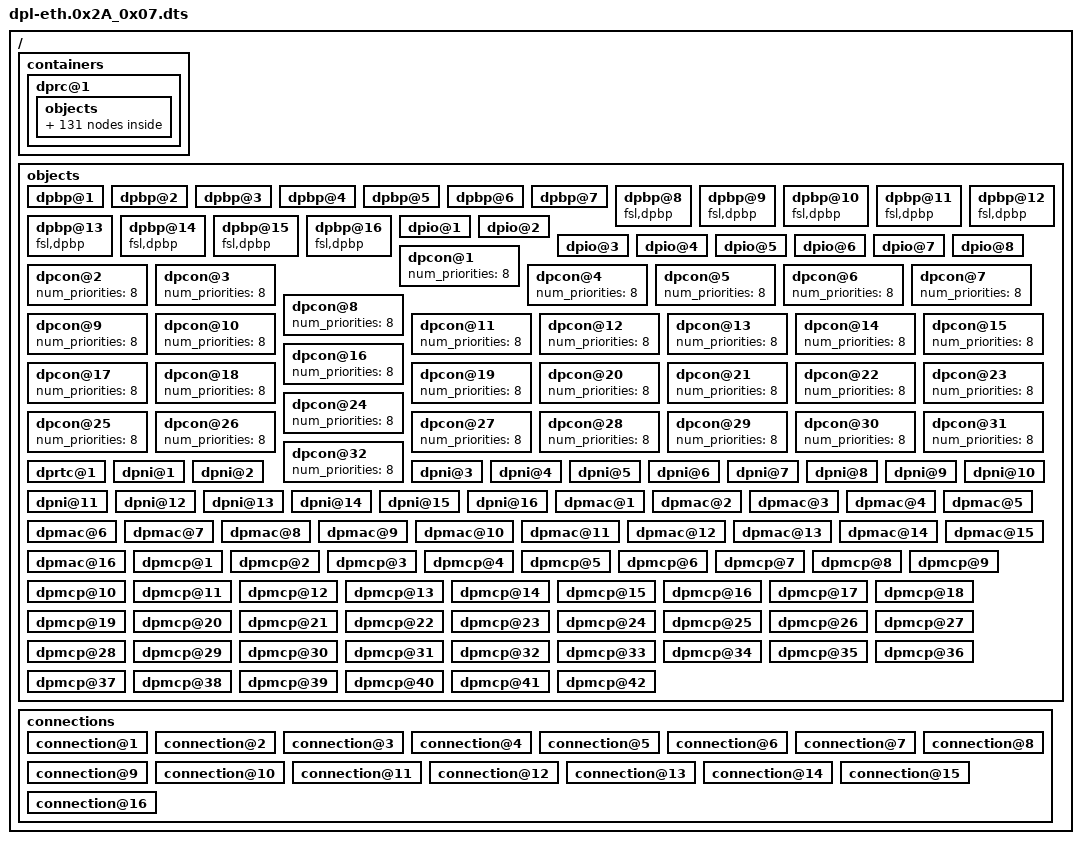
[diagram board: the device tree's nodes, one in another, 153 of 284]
/*
 * Copyright 2015-2016 Freescale Semiconductor, Inc.
 * Copyright 2017 NXP
 *
 * Redistribution and use in source and binary forms, with or without
 * modification, are permitted provided that the following conditions are met:
 *   * Redistributions of source code must retain the above copyright
 *     notice, this list of conditions and the following disclaimer.
 *   * Redistributions in binary form must reproduce the above copyright
 *     notice, this list of conditions and the following disclaimer in the
 *     documentation and/or other materials provided with the distribution.
 *   * Neither the name of the above-listed copyright holders nor the
 *     names of any contributors may be used to endorse or promote products
 *     derived from this software without specific prior written permission.
 *
 * THIS SOFTWARE IS PROVIDED BY THE COPYRIGHT HOLDERS AND CONTRIBUTORS "AS IS"
 * AND ANY EXPRESS OR IMPLIED WARRANTIES, INCLUDING, BUT NOT LIMITED TO, THE
 * IMPLIED WARRANTIES OF MERCHANTABILITY AND FITNESS FOR A PARTICULAR PURPOSE
 * ARE DISCLAIMED. IN NO EVENT SHALL THE COPYRIGHT HOLDERS OR CONTRIBUTORS BE
 * LIABLE FOR ANY DIRECT, INDIRECT, INCIDENTAL, SPECIAL, EXEMPLARY, OR
 * CONSEQUENTIAL DAMAGES (INCLUDING, BUT NOT LIMITED TO, PROCUREMENT OF
 * SUBSTITUTE GOODS OR SERVICES; LOSS OF USE, DATA, OR PROFITS; OR BUSINESS
 * INTERRUPTION) HOWEVER CAUSED AND ON ANY THEORY OF LIABILITY, WHETHER IN
 * CONTRACT, STRICT LIABILITY, OR TORT (INCLUDING NEGLIGENCE OR OTHERWISE)
 * ARISING IN ANY WAY OUT OF THE USE OF THIS SOFTWARE, EVEN IF ADVISED OF THE
 * POSSIBILITY OF SUCH DAMAGE.
 */

/*
 * This DPL showcases one Linux configuration for SerDes 0x2a_0x07
 */

/dts-v1/;
/ {
	/*****************************************************************
         * Containers
         *****************************************************************/
	containers {
		dprc@1 {
			parent = "none";
			options = "DPRC_CFG_OPT_SPAWN_ALLOWED" , "DPRC_CFG_OPT_ALLOC_ALLOWED", "DPRC_CFG_OPT_IRQ_CFG_ALLOWED";

			objects {
				/* ------------- DPMACs --------------*/
				/* For SerDes 0x2a_07, 8 DPMACs are mapped
				 * on the 8 XFI ports and 8 DPMACs
				 * are mapped on the 8 SGMII ports of the PCIe
				 * Slot 4 riser card.
				 */
				obj@101 {
					obj_name = "dpmac@1";
				};
				obj@102 {
					obj_name = "dpmac@2";
				};
				obj@103 {
					obj_name = "dpmac@3";
				};
				obj@104 {
					obj_name = "dpmac@4";
				};
				obj@105 {
					obj_name = "dpmac@5";
				};
				obj@106 {
					obj_name = "dpmac@6";
				};
				obj@107 {
					obj_name = "dpmac@7";
				};
				obj@108 {
					obj_name = "dpmac@8";
				};
				obj@109 {
					obj_name = "dpmac@9";
				};
				obj@110 {
					obj_name = "dpmac@10";
				};
				obj@111 {
					obj_name = "dpmac@11";
				};
				obj@112 {
					obj_name = "dpmac@12";
				};
				obj@113 {
					obj_name = "dpmac@13";
				};
				obj@114 {
					obj_name = "dpmac@14";
				};
				obj@115 {
					obj_name = "dpmac@15";
				};
				obj@116 {
					obj_name = "dpmac@16";
				};

				/* ------------ DPNIs --------------*/
				obj@201 {
					obj_name = "dpni@1";
				};
				obj@202 {
					obj_name = "dpni@2";
				};
				obj@203 {
					obj_name = "dpni@3";
				};
				obj@204 {
					obj_name = "dpni@4";
				};
				obj@205 {
					obj_name = "dpni@5";
				};
				obj@206 {
					obj_name = "dpni@6";
				};
				obj@207 {
					obj_name = "dpni@7";
				};
				obj@208 {
					obj_name = "dpni@8";
				};
				obj@209 {
					obj_name = "dpni@9";
				};
				obj@210 {
					obj_name = "dpni@10";
				};
				obj@211 {
					obj_name = "dpni@11";
				};
				obj@212 {
					obj_name = "dpni@12";
				};
				obj@213 {
					obj_name = "dpni@13";
				};
				obj@214 {
					obj_name = "dpni@14";
				};
				obj@215 {
					obj_name = "dpni@15";
				};
				obj@216 {
					obj_name = "dpni@16";
				};

				/* ------------ DPBPs --------------*/
				/* Each DPNI uses one DPBP */
				obj@301 {
					obj_name="dpbp@1";
				};
				obj@302 {
					obj_name="dpbp@2";
				};
				obj@303 {
					obj_name="dpbp@3";
				};
				obj@304 {
					obj_name="dpbp@4";
				};
				obj@305 {
					obj_name="dpbp@5";
				};
				obj@306 {
					obj_name="dpbp@6";
				};
				obj@307 {
					obj_name="dpbp@7";
				};
				obj@308 {
					obj_name = "dpbp@8";
				};
				obj@309 {
					obj_name = "dpbp@9";
				};
				obj@310 {
					obj_name = "dpbp@10";
				};
				obj@311 {
					obj_name = "dpbp@11";
				};
				obj@312 {
					obj_name = "dpbp@12";
				};
				obj@313 {
					obj_name = "dpbp@13";
				};
				obj@314 {
					obj_name = "dpbp@14";
				};
				obj@315 {
					obj_name = "dpbp@15";
				};
				obj@316 {
					obj_name = "dpbp@16";
				};


				/* ------------ DPMCPs --------------*/
				/* Ethernet DPMCPs:
				*  One for every DPNI, one for every DPMAC, then
				*  one more for DPIO.
				*
				*  Next: DPRC and restool, VFIO and possibly
				*  others from the kernel have DPMCP requirements.
				*  We'll just add a slack of 10 MCPs.
				*/
				obj@801 {
					obj_name="dpmcp@1";
				};
				obj@802 {
					obj_name="dpmcp@2";
				};
				obj@803 {
					obj_name="dpmcp@3";
				};
				obj@804 {
					obj_name="dpmcp@4";
				};
				obj@805 {
					obj_name="dpmcp@5";
				};
				obj@806 {
					obj_name="dpmcp@6";
				};
				obj@807 {
					obj_name="dpmcp@7";
				};
				obj@808 {
					obj_name="dpmcp@8";
				};
				obj@809 {
					obj_name="dpmcp@9";
				};
				obj@810 {
					obj_name="dpmcp@10";
				};
				obj@811 {
					obj_name="dpmcp@11";
				};
				obj@812 {
					obj_name="dpmcp@12";
				};
				obj@813 {
					obj_name="dpmcp@13";
				};
				obj@814 {
					obj_name="dpmcp@14";
				};
				obj@815 {
					obj_name="dpmcp@15";
				};
				obj@816 {
					obj_name="dpmcp@16";
				};
				obj@817 {
					obj_name="dpmcp@17";
				};
				obj@818 {
					obj_name="dpmcp@18";
				};
				obj@819 {
					obj_name="dpmcp@19";
				};
				obj@820 {
					obj_name="dpmcp@20";
				};
				obj@821 {
					obj_name="dpmcp@21";
				};
				obj@822 {
					obj_name="dpmcp@22";
				};
				obj@823 {
					obj_name="dpmcp@23";
				};
				obj@824 {
					obj_name="dpmcp@24";
				};
				obj@825 {
					obj_name="dpmcp@25";
				};
				obj@826 {
					obj_name="dpmcp@26";
				};
				obj@827 {
					obj_name="dpmcp@27";
				};
				obj@828 {
					obj_name="dpmcp@28";
				};
				obj@829 {
					obj_name="dpmcp@29";
				};
				obj@830 {
					obj_name="dpmcp@30";
				};
				obj@831 {
					obj_name="dpmcp@31";
				};
				obj@832 {
					obj_name="dpmcp@32";
				};
				obj@833 {
					obj_name="dpmcp@33";
				};
				obj@834 {
					obj_name="dpmcp@34";
				};
				obj@835 {
					obj_name="dpmcp@35";
				};
				obj@836 {
					obj_name="dpmcp@36";
				};
				obj@837 {
					obj_name="dpmcp@37";
				};
				obj@838 {
					obj_name="dpmcp@38";
				};
				obj@839 {
					obj_name="dpmcp@39";
				};
				obj@840 {
					obj_name="dpmcp@40";
				};
				obj@841 {
					obj_name="dpmcp@41";
				};
				obj@842 {
					obj_name="dpmcp@42";
				};
				/* ------------ DPIOs --------------*/
				/* One DPIO for each online CPU. This is a
				 * maximal configuration.
				 */
				obj@401 {
					obj_name = "dpio@1";
				};
				obj@402 {
					obj_name = "dpio@2";
				};
				obj@403 {
					obj_name = "dpio@3";
				};
				obj@404 {
					obj_name = "dpio@4";
				};
				obj@405 {
					obj_name = "dpio@5";
				};
				obj@406 {
					obj_name = "dpio@6";
				};
				obj@407 {
					obj_name = "dpio@7";
				};
				obj@408 {
					obj_name = "dpio@8";
				};

				/* ------------ DPCONs --------------*/
				/* Used by DPNIs in Linux for CDAN-based dequeueing.
				 * Ideally, there should be one DPCON per {DPNIxDPIO}
				 * combination. but at the moment we're constrained
				 * by the hard limit of 64 8-prio DPCONs. Moreover,
				 * each DPIO object consumes one DPCON, so there are
				 * only 56 left for all DPNIs
				 */
				obj@501 {
					obj_name="dpcon@1";
				};
				obj@502 {
					obj_name="dpcon@2";
				};
				obj@503 {
					obj_name="dpcon@3";
				};
				obj@504 {
					obj_name="dpcon@4";
				};
				obj@505 {
					obj_name="dpcon@5";
				};
				obj@506 {
					obj_name="dpcon@6";
				};
				obj@507 {
					obj_name="dpcon@7";
				};
				obj@508 {
					obj_name="dpcon@8";
				};
				obj@509 {
					obj_name="dpcon@9";
				};
				obj@510 {
					obj_name="dpcon@10";
				};
				obj@511 {
					obj_name="dpcon@11";
				};
				obj@512 {
					obj_name="dpcon@12";
				};
				obj@513 {
					obj_name="dpcon@13";
				};
				obj@514 {
					obj_name="dpcon@14";
				};
				obj@515 {
					obj_name="dpcon@15";
				};
				obj@516 {
					obj_name="dpcon@16";
				};
				obj@517 {
					obj_name="dpcon@17";
				};
				obj@518 {
					obj_name="dpcon@18";
				};
				obj@519 {
					obj_name="dpcon@19";
				};
				obj@520 {
					obj_name="dpcon@20";
				};
				obj@521 {
					obj_name="dpcon@21";
				};
				obj@522 {
					obj_name="dpcon@22";
				};
				obj@523 {
					obj_name="dpcon@23";
				};
				obj@524 {
					obj_name="dpcon@24";
				};
				obj@525 {
					obj_name="dpcon@25";
				};
				obj@526 {
					obj_name="dpcon@26";
				};
				obj@527 {
					obj_name="dpcon@27";
				};
				obj@528 {
					obj_name="dpcon@28";
				};
				obj@529 {
					obj_name="dpcon@29";
				};
				obj@530 {
					obj_name="dpcon@30";
				};
				obj@531 {
					obj_name="dpcon@31";
				};
				obj@532 {
					obj_name="dpcon@32";
				};

				/* ------------ DPRTC --------------*/
				obj@901 {
					obj_name="dprtc@1";
				};
			};
		};
	};

	/*****************************************************************
         * Objects
         *****************************************************************/
	objects {

		/* ------------ DPBP --------------*/
		dpbp@1 {
		};
		dpbp@2 {
		};
		dpbp@3 {
		};
		dpbp@4 {
		};
		dpbp@5 {
		};
		dpbp@6 {
		};
		dpbp@7 {
		};
		dpbp@8 {
			compatible= "fsl,dpbp";
		};
		dpbp@9 {
			compatible= "fsl,dpbp";
		};
		dpbp@10 {
			compatible= "fsl,dpbp";
		};
		dpbp@11 {
			compatible= "fsl,dpbp";
		};
		dpbp@12 {
			compatible= "fsl,dpbp";
		};
		dpbp@13 {
			compatible= "fsl,dpbp";
		};
		dpbp@14 {
			compatible= "fsl,dpbp";
		};
		dpbp@15 {
			compatible= "fsl,dpbp";
		};
		dpbp@16 {
			compatible= "fsl,dpbp";
		};
		/* ------------ DPIO --------------*/
		dpio@1 {
			channel_mode = "DPIO_LOCAL_CHANNEL";
			num_priorities = <8>;
		};
		dpio@2 {
			channel_mode = "DPIO_LOCAL_CHANNEL";
			num_priorities = <8>;
		};
		dpio@3 {
			channel_mode = "DPIO_LOCAL_CHANNEL";
			num_priorities = <8>;
		};
		dpio@4 {
			channel_mode = "DPIO_LOCAL_CHANNEL";
			num_priorities = <8>;
		};
		dpio@5 {
			channel_mode = "DPIO_LOCAL_CHANNEL";
			num_priorities = <8>;
		};
		dpio@6 {
			channel_mode = "DPIO_LOCAL_CHANNEL";
			num_priorities = <8>;
		};
		dpio@7 {
			channel_mode = "DPIO_LOCAL_CHANNEL";
			num_priorities = <8>;
		};
		dpio@8 {
			channel_mode = "DPIO_LOCAL_CHANNEL";
			num_priorities = <8>;
		};
		/* ------------ DPCON --------------*/
		/* Currently, only 8-WQ channels are supported. */
		dpcon@1 {
			num_priorities=<8>;
		};
		dpcon@2 {
			num_priorities=<8>;
		};
		dpcon@3 {
			num_priorities=<8>;
		};
		dpcon@4 {
			num_priorities=<8>;
		};
		dpcon@5 {
			num_priorities=<8>;
		};
		dpcon@6 {
			num_priorities=<8>;
		};
		dpcon@7 {
			num_priorities=<8>;
		};
		dpcon@8 {
			num_priorities=<8>;
		};
		dpcon@9 {
			num_priorities=<8>;
		};
		dpcon@10 {
			num_priorities=<8>;
		};
		dpcon@11 {
			num_priorities=<8>;
		};
		dpcon@12 {
			num_priorities=<8>;
		};
		dpcon@13 {
			num_priorities=<8>;
		};
		dpcon@14 {
			num_priorities=<8>;
		};
		dpcon@15 {
			num_priorities=<8>;
		};
		dpcon@16 {
			num_priorities=<8>;
		};
		dpcon@17 {
			num_priorities=<8>;
		};
		dpcon@18 {
			num_priorities=<8>;
		};
		dpcon@19 {
			num_priorities=<8>;
		};
		dpcon@20 {
			num_priorities=<8>;
		};
		dpcon@21 {
			num_priorities=<8>;
		};
		dpcon@22 {
			num_priorities=<8>;
		};
		dpcon@23 {
			num_priorities=<8>;
		};
		dpcon@24 {
			num_priorities=<8>;
		};
		dpcon@25 {
			num_priorities=<8>;
		};
		dpcon@26 {
			num_priorities=<8>;
		};
		dpcon@27 {
			num_priorities=<8>;
		};
		dpcon@28 {
			num_priorities=<8>;
		};
		dpcon@29 {
			num_priorities=<8>;
		};
		dpcon@30 {
			num_priorities=<8>;
		};
		dpcon@31 {
			num_priorities=<8>;
		};
		dpcon@32 {
			num_priorities=<8>;
		};

		/* ------------ DPRTC --------------*/
		dprtc@1 {
		};

		/* ------------ DPNI --------------*/
		/* Common DPNI properties:
		 *
		 * mac_addr = <0x00 0x00 0x00 0x00 0x00 0x00>;
		 *   An all-zero value will cause the Eth driver to auto-generate
		 *   a random (but valid) MAC address. Reduces DPL maintenance.
		 *
		 * max_senders = <8>;
		 *   Number of DPIOs to use for transmission.
		 *
		 * max_dist_per_tc = <7>;
		 *   Number of Rx cores to configure hash distribution towards.
		 *   Un-intuitively, '7' actually means '8' ("add 1 and round to
		 *   the nearest power of 2").
		 *
		 * max_dist_key_size = <24>;
		 *    Maximum hash key length in bytes.
		 *
		 * Other possible properties:
		 *  max_unicast_filters
		 *  max_multicast_filters
		 *  max_vlan_filters
		 *  max_qos_entries
		 *  max_qos_key_size
		 *
		 * Unless otherwise stated, attributes with value <0> receive a
		 * default value from the MC and can be skipped from the DPL
		 * altogether.
		 */
		dpni@1 {
			type = "DPNI_TYPE_NIC";
			mac_addr = <0x00 0x00 0x00 0x00 0x00 0x00>;
			max_senders = <8>;
			options = "DPNI_OPT_MULTICAST_FILTER", "DPNI_OPT_UNICAST_FILTER", "DPNI_OPT_DIST_HASH", "DPNI_OPT_DIST_FS";
			max_tcs = <1>;
			max_dist_per_tc = <1>;
			max_dist_key_size = <24>;
		};
		dpni@2 {
			type = "DPNI_TYPE_NIC";
			mac_addr = <0x00 0x00 0x00 0x00 0x00 0x00>;
			max_senders = <8>;
			options = "DPNI_OPT_MULTICAST_FILTER", "DPNI_OPT_UNICAST_FILTER", "DPNI_OPT_DIST_HASH", "DPNI_OPT_DIST_FS";
			max_tcs = <1>;
			max_dist_per_tc = <1>;
			max_dist_key_size = <24>;
		};
		dpni@3 {
			type = "DPNI_TYPE_NIC";
			mac_addr = <0x00 0x00 0x00 0x00 0x00 0x00>;
			max_senders = <8>;
			options = "DPNI_OPT_MULTICAST_FILTER", "DPNI_OPT_UNICAST_FILTER", "DPNI_OPT_DIST_HASH", "DPNI_OPT_DIST_FS";
			max_tcs = <1>;
			max_dist_per_tc = <1>;
			max_dist_key_size = <24>;
		};
		dpni@4 {
			type = "DPNI_TYPE_NIC";
			mac_addr = <0x00 0x00 0x00 0x00 0x00 0x00>;
			max_senders = <8>;
			options = "DPNI_OPT_MULTICAST_FILTER", "DPNI_OPT_UNICAST_FILTER", "DPNI_OPT_DIST_HASH", "DPNI_OPT_DIST_FS";
			max_tcs = <1>;
			max_dist_per_tc = <1>;
			max_dist_key_size = <24>;
		};
		dpni@5 {
			type = "DPNI_TYPE_NIC";
			mac_addr = <0x00 0x00 0x00 0x00 0x00 0x00>;
			max_senders = <8>;
			options = "DPNI_OPT_MULTICAST_FILTER", "DPNI_OPT_UNICAST_FILTER", "DPNI_OPT_DIST_HASH", "DPNI_OPT_DIST_FS";
			max_tcs = <1>;
			max_dist_per_tc = <1>;
			max_dist_key_size = <24>;
		};
		dpni@6 {
			type = "DPNI_TYPE_NIC";
			mac_addr = <0x00 0x00 0x00 0x00 0x00 0x00>;
			max_senders = <8>;
			options = "DPNI_OPT_MULTICAST_FILTER", "DPNI_OPT_UNICAST_FILTER", "DPNI_OPT_DIST_HASH", "DPNI_OPT_DIST_FS";
			max_tcs = <1>;
			max_dist_per_tc = <1>;
			max_dist_key_size = <24>;
		};
		dpni@7 {
			type = "DPNI_TYPE_NIC";
			mac_addr = <0x00 0x00 0x00 0x00 0x00 0x00>;
			max_senders = <8>;
			options = "DPNI_OPT_MULTICAST_FILTER", "DPNI_OPT_UNICAST_FILTER", "DPNI_OPT_DIST_HASH", "DPNI_OPT_DIST_FS";
			max_tcs = <1>;
			max_dist_per_tc = <1>;
			max_dist_key_size = <24>;
		};
		dpni@8 {
			type = "DPNI_TYPE_NIC";
			mac_addr = <0x00 0x00 0x00 0x00 0x00 0x00>;
			max_senders = <8>;
			options = "DPNI_OPT_MULTICAST_FILTER", "DPNI_OPT_UNICAST_FILTER", "DPNI_OPT_DIST_HASH", "DPNI_OPT_DIST_FS";
			max_tcs = <1>;
			max_dist_per_tc = <1>;
			max_dist_key_size = <24>;
		};
		dpni@9 {
			type = "DPNI_TYPE_NIC";
			mac_addr = <0x00 0x00 0x00 0x00 0x00 0x00>;
			max_senders = <8>;
			options = "DPNI_OPT_MULTICAST_FILTER", "DPNI_OPT_UNICAST_FILTER", "DPNI_OPT_DIST_HASH", "DPNI_OPT_DIST_FS";
			max_tcs = <1>;
			max_dist_per_tc = <1>;
			max_dist_key_size = <24>;
		};
		dpni@10 {
			type = "DPNI_TYPE_NIC";
			mac_addr = <0x00 0x00 0x00 0x00 0x00 0x00>;
			max_senders = <8>;
			options = "DPNI_OPT_MULTICAST_FILTER", "DPNI_OPT_UNICAST_FILTER", "DPNI_OPT_DIST_HASH", "DPNI_OPT_DIST_FS";
			max_tcs = <1>;
			max_dist_per_tc = <1>;
			max_dist_key_size = <24>;
		};
		dpni@11 {
			type = "DPNI_TYPE_NIC";
			mac_addr = <0x00 0x00 0x00 0x00 0x00 0x00>;
			max_senders = <8>;
			options = "DPNI_OPT_MULTICAST_FILTER", "DPNI_OPT_UNICAST_FILTER", "DPNI_OPT_DIST_HASH", "DPNI_OPT_DIST_FS";
			max_tcs = <1>;
			max_dist_per_tc = <1>;
			max_dist_key_size = <24>;
		};
		dpni@12 {
			type = "DPNI_TYPE_NIC";
			mac_addr = <0x00 0x00 0x00 0x00 0x00 0x00>;
			max_senders = <8>;
			options = "DPNI_OPT_MULTICAST_FILTER", "DPNI_OPT_UNICAST_FILTER", "DPNI_OPT_DIST_HASH", "DPNI_OPT_DIST_FS";
			max_tcs = <1>;
			max_dist_per_tc = <1>;
			max_dist_key_size = <24>;
		};
		dpni@13 {
			type = "DPNI_TYPE_NIC";
			mac_addr = <0x00 0x00 0x00 0x00 0x00 0x00>;
			max_senders = <8>;
			options = "DPNI_OPT_MULTICAST_FILTER", "DPNI_OPT_UNICAST_FILTER", "DPNI_OPT_DIST_HASH", "DPNI_OPT_DIST_FS";
			max_tcs = <1>;
			max_dist_per_tc = <1>;
			max_dist_key_size = <24>;
		};
		dpni@14 {
			type = "DPNI_TYPE_NIC";
			mac_addr = <0x00 0x00 0x00 0x00 0x00 0x00>;
			max_senders = <8>;
			options = "DPNI_OPT_MULTICAST_FILTER", "DPNI_OPT_UNICAST_FILTER", "DPNI_OPT_DIST_HASH", "DPNI_OPT_DIST_FS";
			max_tcs = <1>;
			max_dist_per_tc = <1>;
			max_dist_key_size = <24>;
		};
		dpni@15 {
			type = "DPNI_TYPE_NIC";
			mac_addr = <0x00 0x00 0x00 0x00 0x00 0x00>;
			max_senders = <8>;
			options = "DPNI_OPT_MULTICAST_FILTER", "DPNI_OPT_UNICAST_FILTER", "DPNI_OPT_DIST_HASH", "DPNI_OPT_DIST_FS";
			max_tcs = <1>;
			max_dist_per_tc = <1>;
			max_dist_key_size = <24>;
		};
		dpni@16 {
			type = "DPNI_TYPE_NIC";
			mac_addr = <0x00 0x00 0x00 0x00 0x00 0x00>;
			max_senders = <8>;
			options = "DPNI_OPT_MULTICAST_FILTER", "DPNI_OPT_UNICAST_FILTER", "DPNI_OPT_DIST_HASH", "DPNI_OPT_DIST_FS";
			max_tcs = <1>;
			max_dist_per_tc = <1>;
			max_dist_key_size = <24>;
		};

		/* ------------ DPMAC --------------*/
		dpmac@1 {
		};
		dpmac@2 {
		};
		dpmac@3 {
		};
		dpmac@4 {
		};
		dpmac@5 {
		};
		dpmac@6 {
		};
		dpmac@7 {
		};
		dpmac@8 {
		};
		dpmac@9 {
		};
		dpmac@10 {
		};
		dpmac@11 {
		};
		dpmac@12 {
		};
		dpmac@13 {
		};
		dpmac@14 {
		};
		dpmac@15 {
		};
		dpmac@16 {
		};

		/* ------------ DPMCP --------------*/
		dpmcp@1 {
		};
		dpmcp@2 {
		};
		dpmcp@3 {
		};
		dpmcp@4 {
		};
		dpmcp@5 {
		};
		dpmcp@6 {
		};
		dpmcp@7 {
		};
		dpmcp@8 {
		};
		dpmcp@9 {
		};
		dpmcp@10 {
		};
		dpmcp@11 {
		};
		dpmcp@12 {
		};
		dpmcp@13 {
		};
		dpmcp@14 {
		};
		dpmcp@15 {
		};
		dpmcp@16 {
		};
		dpmcp@17 {
		};
		dpmcp@18 {
		};
		dpmcp@19 {
		};
		dpmcp@20 {
		};
		dpmcp@21 {
		};
		dpmcp@22 {
		};
		dpmcp@23 {
		};
		dpmcp@24 {
		};
		dpmcp@25 {
		};
		dpmcp@26 {
		};
		dpmcp@27 {
		};
		dpmcp@28 {
		};
		dpmcp@29 {
		};
		dpmcp@30 {
		};
		dpmcp@31 {
		};
		dpmcp@32 {
		};
		dpmcp@33 {
		};
		dpmcp@34 {
		};
		dpmcp@35 {
		};
		dpmcp@36 {
		};
		dpmcp@37 {
		};
		dpmcp@38 {
		};
		dpmcp@39 {
		};
		dpmcp@40 {
		};
		dpmcp@41 {
		};
		dpmcp@42 {
		};
	};

	/*****************************************************************
         * Connections
         *****************************************************************/
	connections {
		/* XFIs */
		connection@1{
			endpoint1 = "dpni@1";
			endpoint2 = "dpmac@1";
		};
		connection@2{
			endpoint1 = "dpni@2";
			endpoint2 = "dpmac@2";
		};
		connection@3{
			endpoint1 = "dpni@3";
			endpoint2 = "dpmac@3";
		};
		connection@4{
			endpoint1 = "dpni@4";
			endpoint2 = "dpmac@4";
		};
		connection@5{
			endpoint1 = "dpni@5";
			endpoint2 = "dpmac@5";
		};
		connection@6{
			endpoint1 = "dpni@6";
			endpoint2 = "dpmac@6";
		};
		connection@7{
			endpoint1 = "dpni@7";
			endpoint2 = "dpmac@7";
		};
		connection@8{
			endpoint1 = "dpni@8";
			endpoint2 = "dpmac@8";
		};
	/* SGMIIs */
		connection@9{
			endpoint1 = "dpni@9";
			endpoint2 = "dpmac@9";
		};
		connection@10{
			endpoint1 = "dpni@10";
			endpoint2 = "dpmac@10";
		};
		connection@11{
			endpoint1 = "dpni@11";
			endpoint2 = "dpmac@11";
		};
		connection@12{
			endpoint1 = "dpni@12";
			endpoint2 = "dpmac@12";
		};
		connection@13{
			endpoint1 = "dpni@13";
			endpoint2 = "dpmac@13";
		};
		connection@14{
			endpoint1 = "dpni@14";
			endpoint2 = "dpmac@14";
		};
		connection@15{
			endpoint1 = "dpni@15";
			endpoint2 = "dpmac@15";
		};
		connection@16{
			endpoint1 = "dpni@16";
			endpoint2 = "dpmac@16";
		};
	};
};
